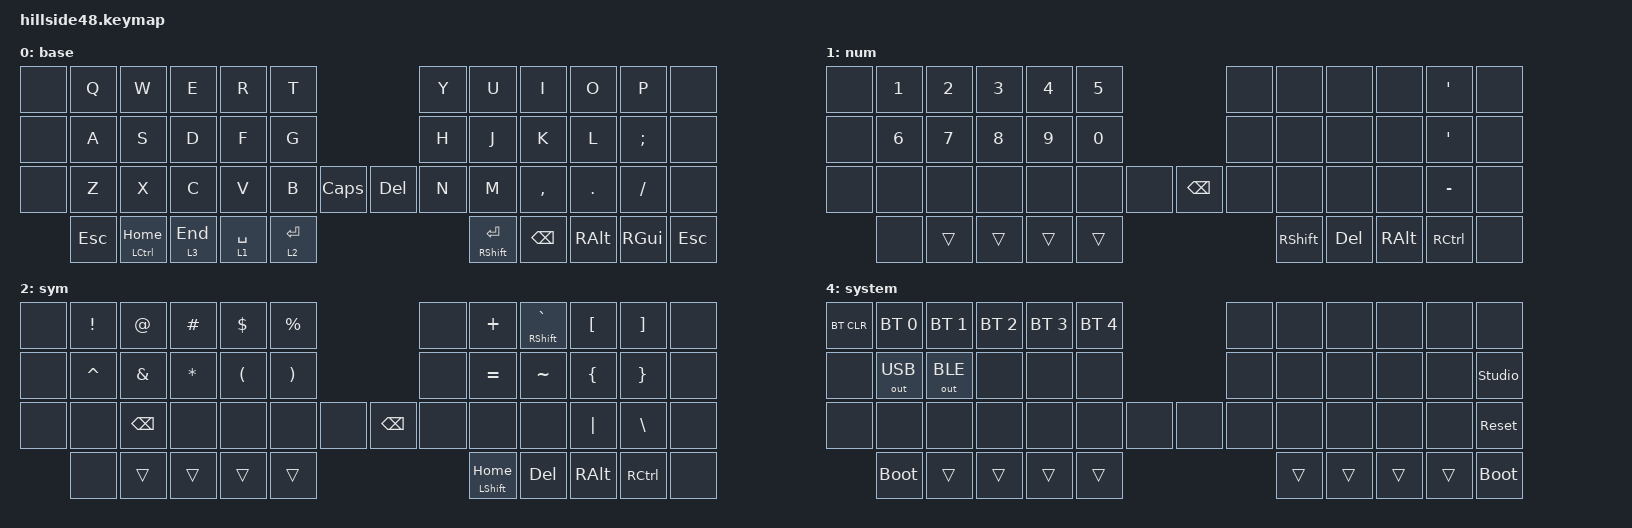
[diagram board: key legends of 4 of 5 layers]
#include <behaviors.dtsi>
#include <dt-bindings/zmk/keys.h>
#include <dt-bindings/zmk/bt.h>
#include <dt-bindings/zmk/outputs.h>
#include <dt-bindings/zmk/pointing.h>

&mt { tapping-term-ms = <200>; };
&lt { tapping-term-ms = <200>; };

/ {
  conditional_layers {
    compatible = "zmk,conditional-layers";
    adjust { if-layers = <1 2>; then-layer = <4>; };
  };

  keymap {
    compatible = "zmk,keymap";

    base {
      bindings = <
&none  &kp Q  &kp W  &kp E  &kp R  &kp T                            &kp Y  &kp U  &kp I      &kp O    &kp P     &none
&none  &kp A  &kp S  &kp D  &kp F  &kp G                            &kp H  &kp J  &kp K      &kp L    &kp SEMI  &none
&none  &kp Z  &kp X  &kp C  &kp V  &kp B  &kp CAPS       &kp DEL    &kp N  &kp M  &kp COMMA  &kp DOT  &kp FSLH  &none
    &kp ESC  &mt LCTRL HOME  &lt 3 END  &lt 1 SPACE  &lt 2 RET      &mt RSHFT RET  &kp BSPC  &kp RALT  &kp RGUI  &kp ESC
      >;
    };

    num {
      bindings = <
&none  &kp N1  &kp N2  &kp N3  &kp N4  &kp N5                       &none  &none  &none  &none  &kp SQT    &none
&none  &kp N6  &kp N7  &kp N8  &kp N9  &kp N0                       &none  &none  &none  &none  &kp SQT    &none
&none  &none   &none   &none   &none   &none  &none      &kp BSPC   &none  &none  &none  &none  &kp MINUS  &none
       &none  &trans  &trans  &trans  &trans                        &kp RSHFT  &kp DEL  &kp RALT  &kp RCTRL  &none
      >;
    };

    sym {
      bindings = <
&none  &kp EXCL   &kp AT    &kp HASH  &kp DLLR  &kp PRCNT                      &none  &kp PLUS   &mt RSHFT GRAVE  &kp LBKT  &kp RBKT  &none
&none  &kp CARET  &kp AMPS  &kp STAR  &kp LPAR  &kp RPAR                       &none  &kp EQUAL  &kp TILDE        &kp LBRC  &kp RBRC  &none
&none  &none      &kp BSPC  &none     &none     &none  &none       &kp BSPC    &none  &none      &none            &kp PIPE  &kp BSLH  &none
       &none  &trans  &trans  &trans  &trans                                   &mt LSHFT HOME  &kp DEL  &kp RALT  &kp RCTRL  &none
      >;
    };

    nav {
      bindings = <
&none  &kp C_AC_BACK  &kp LEFT  &kp UP    &kp RIGHT  &kp C_AC_FORWARD                     &mkp LCLK  &mmv MOVE_LEFT  &mmv MOVE_UP    &mmv MOVE_RIGHT  &mkp RCLK  &none
&none  &kp TAB        &kp LALT  &kp DOWN  &kp PG_UP  &none                                &none      &kp RSHFT       &mmv MOVE_DOWN  &none            &none      &none
&none  &none          &none     &none     &kp PG_DN  &none  &none          &kp BSPC       &none      &none           &none           &none            &none      &none
       &none  &trans  &trans  &trans  &trans                                              &mt RSHFT HOME  &kp DEL  &kp END  &none
      >;
    };

    system {
      bindings = <
&bt BT_CLR  &bt BT_SEL 0  &bt BT_SEL 1  &bt BT_SEL 2  &bt BT_SEL 3  &bt BT_SEL 4                    &none  &none  &none  &none  &none  &none
&none       &out OUT_USB  &out OUT_BLE  &none         &none         &none                           &none  &none  &none  &none  &none  &studio_unlock
&none       &none         &none         &none         &none         &none  &none          &none     &none  &none  &none  &none  &none  &sys_reset
       &bootloader  &trans  &trans  &trans  &trans                                        &trans  &trans  &trans  &trans  &bootloader
      >;
    };
  };
};
